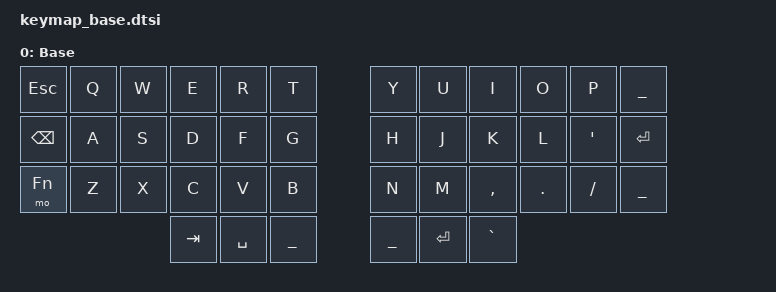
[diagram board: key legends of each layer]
#include <behaviors.dtsi>
#include <dt-bindings/zmk/keys.h>

#include "../zmk-nodefree-config/helper.h"
#include "../zmk-nodefree-config/keypos_def/keypos_36keys.h"
#include "../zmk-nodefree-config/international_chars/german.dtsi"

// homerow mods
ZMK_BEHAVIOR(hrm, hold_tap,
    flavor = "balanced";
    tapping-term-ms = <280>;
    quick-tap-ms = <125>;
    bindings = <&kp>, <&kp>;
)

// tap: sticky shift | double tap: capsword
ZMK_BEHAVIOR(ss_cw, tap_dance,
    tapping-term-ms = <200>;
    bindings = <&sk LSHFT>, <&caps_word>;
)

// tap: backspace | shift + tap: delete | hold: num layer
ZMK_BEHAVIOR(bs_del_num, mod_morph,
    bindings = <&lt NUM BSPC>, <&kp DEL>;
    mods = <(MOD_LSFT|MOD_RSFT)>;
)

// windows sleep macro
ZMK_BEHAVIOR(win_sleep, macro,
    wait-ms = <100>;
    tap-ms = <5>;
    bindings = <&kp LG(X) &kp U &kp S>;
)

/ {
  keymap {
    compatible = "zmk,keymap";

    layer_base {
      label = "Base";
            bindings = <

// ╭───────────────┬───────────────┬───────────────┬───────────────┬───────────────┬───────────────╮   ╭───────────────┬───────────────┬───────────────┬───────────────┬───────────────┬───────────────╮
//  0               1               2               3               4               5                   6               7               8               9               10              11
    &kp ESC         &kp Q           &kp W           &kp E           &kp R           &kp T               &kp Y           &kp U           &kp I           &kp O           &kp P           ___
// ├───────────────├───────────────┼───────────────┼───────────────┼───────────────┼───────────────┤   ├───────────────├───────────────┼───────────────┼───────────────┼───────────────┼───────────────┤
//  12              13              14              15              16              17                  18              19              20              21              22              23
    &kp BACKSPACE  &kp A           &kp S           &kp D           &kp F           &kp G               &kp H           &kp J           &kp K           &kp L           &kp SQT         &kp ENTER
// ├───────────────├───────────────┼───────────────┼───────────────┼───────────────┼───────────────┤   ├───────────────├───────────────┼───────────────┼───────────────┼───────────────┼───────────────┤
//  24              25              26              27              28              29                  30              31              32              33              34              35
    &mo Fn            &kp Z           &kp X           &kp C           &kp V           &kp B               &kp N           &kp M           &kp COMMA       &kp DOT         &kp SLASH       ___
// ╰───────────────┴───────────────┴───────────────┼───────────────┼───────────────┼───────────────┤   ├───────────────├───────────────┼───────────────┼───────────────┴───────────────┴───────────────╯
//                                                  36              37              38                  39              40              41
                                                   &kp TAB         &kp SPACE       ___                 ___             &kp ENTER       &kp GRAVE
//                                                 ╰───────────────┴───────────────┴───────────────╯   ╰───────────────┴───────────────┴───────────────╯


            >;

    };
  };
};
